# WKUP_VTM0_ECCAGGR_CFG register map
Vendor: Texas Instruments
Peripheral module from a debugger description file (folder J7VCL).
Registers are 32-bit, access not given, reset 0x0 unless marked. A register's access mark holds for its fields unless they carry their own. Offsets are as the file gives them; lines under a group give offsets from that group; [hi:lo] are bit positions; {n}, {i} and the like mark numbered series; 'fields as' and 'values as' point back to an identical list; <NAME> marks a mode.

## WKUP_VTM0_ECCAGGR_CFG
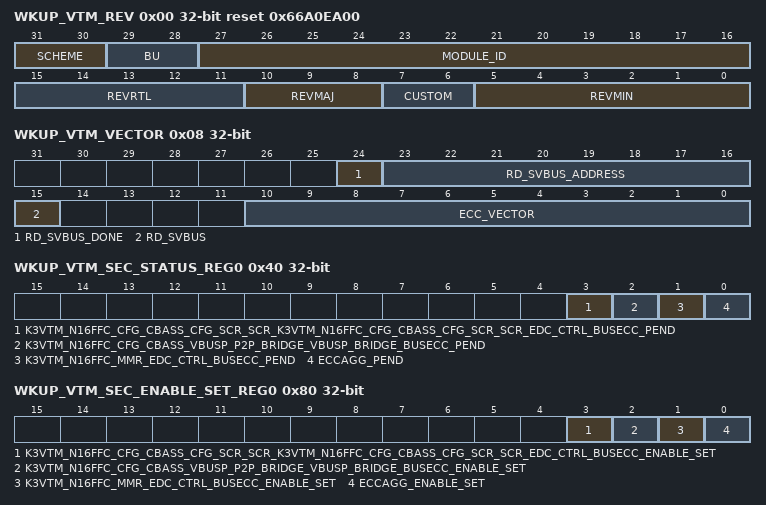
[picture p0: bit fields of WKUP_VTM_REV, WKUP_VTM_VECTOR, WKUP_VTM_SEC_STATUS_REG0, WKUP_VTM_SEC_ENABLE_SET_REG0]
0x00 WKUP_VTM_REV ro reset 0x66A0EA00 — Revision parameters
  [31:30] SCHEME
  [29:28] BU
  [27:16] MODULE_ID
  [15:11] REVRTL — RTL version
  [10:8] REVMAJ — Major version
  [7:6] CUSTOM — Custom version
  [5:0] REVMIN — Minor version
0x08 WKUP_VTM_VECTOR — ECC Register
  [24] RD_SVBUS_DONE — Status to indicate if read on serial VBUS is complete, write of any value will clear this bit. (access RW1C)
  [23:16] RD_SVBUS_ADDRESS rw — Read address
  [15] RD_SVBUS — Write 1 to trigger a read on the serial VBUS (access RW1S)
  [10:0] ECC_VECTOR rw — Value written to select the corresponding ECC RAM for control or status
0x0C WKUP_VTM_STAT ro reset 0x4 — Misc Status
  [10:0] NUM_RAMS — Indicates the number of RAMS serviced by the ECC aggregator
0x10 WKUP_VTM_RESERVED_SVBUS_y rw — Reference other documents that contain the ECC RAM wrapper and EDC controller serial vbus register sets. Offset = 10h + (y * 4h); where y = 0h to 7h
  [31:0] DATA — Serial VBUS register data
0x3C WKUP_VTM_SEC_EOI_REG — EOI Register The EOI register is used to re-trigger the pulse interrupt signal to ensure that any nested interrupt events are serviced. The software interrupt handler must write to the EOI register at the end of the current interrupt processing routine, so that new events can re-trigger the pulse interrupt signal again. For level interrupt signals the EOI register is not functional and must not be used.
  [0] EOI_WR — EOI Register (access RW1S)
0x40 WKUP_VTM_SEC_STATUS_REG0 — Interrupt Status Register 0
  [3] K3VTM_N16FFC_CFG_CBASS_CFG_SCR_SCR_K3VTM_N16FFC_CFG_CBASS_CFG_SCR_SCR_EDC_CTRL_BUSECC_PEND — Interrupt Pending Status for k3vtm_n16ffc_cfg_cbass_cfg_scr_scr_k3vtm_n16ffc_cfg_cbass_cfg_scr_scr_edc_ctrl_busecc_pend (access RW1S)
  [2] K3VTM_N16FFC_CFG_CBASS_VBUSP_P2P_BRIDGE_VBUSP_BRIDGE_BUSECC_PEND — Interrupt Pending Status for k3vtm_n16ffc_cfg_cbass_vbusp_p2p_bridge_vbusp_bridge_busecc_pend (access RW1S)
  [1] K3VTM_N16FFC_MMR_EDC_CTRL_BUSECC_PEND — Interrupt Pending Status for k3vtm_n16ffc_mmr_edc_ctrl_busecc_pend (access RW1S)
  [0] ECCAGG_PEND — Interrupt Pending Status for eccagg_pend (access RW1S)
0x80 WKUP_VTM_SEC_ENABLE_SET_REG0 — Interrupt Enable Set Register 0
  [3] K3VTM_N16FFC_CFG_CBASS_CFG_SCR_SCR_K3VTM_N16FFC_CFG_CBASS_CFG_SCR_SCR_EDC_CTRL_BUSECC_ENABLE_SET — Interrupt Enable Set Register for k3vtm_n16ffc_cfg_cbass_cfg_scr_scr_k3vtm_n16ffc_cfg_cbass_cfg_scr_scr_edc_ctrl_busecc_pend (access RW1S)
  [2] K3VTM_N16FFC_CFG_CBASS_VBUSP_P2P_BRIDGE_VBUSP_BRIDGE_BUSECC_ENABLE_SET — Interrupt Enable Set Register for k3vtm_n16ffc_cfg_cbass_vbusp_p2p_bridge_vbusp_bridge_busecc_pend (access RW1S)
  [1] K3VTM_N16FFC_MMR_EDC_CTRL_BUSECC_ENABLE_SET — Interrupt Enable Set Register for k3vtm_n16ffc_mmr_edc_ctrl_busecc_pend (access RW1S)
  [0] ECCAGG_ENABLE_SET — Interrupt Enable Set Register for eccagg_pend (access RW1S)
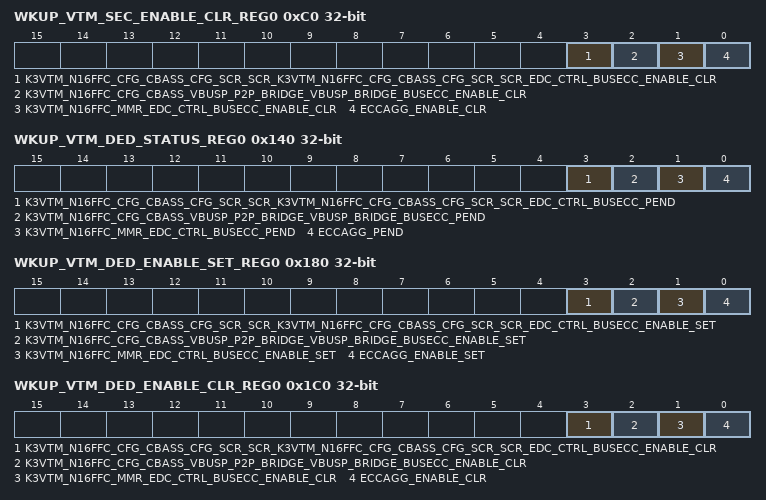
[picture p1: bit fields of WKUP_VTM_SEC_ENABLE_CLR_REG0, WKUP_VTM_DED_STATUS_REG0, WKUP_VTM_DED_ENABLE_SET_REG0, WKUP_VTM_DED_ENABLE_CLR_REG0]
0xC0 WKUP_VTM_SEC_ENABLE_CLR_REG0 — Interrupt Enable Clear Register 0
  [3] K3VTM_N16FFC_CFG_CBASS_CFG_SCR_SCR_K3VTM_N16FFC_CFG_CBASS_CFG_SCR_SCR_EDC_CTRL_BUSECC_ENABLE_CLR — Interrupt Enable Clear Register for k3vtm_n16ffc_cfg_cbass_cfg_scr_scr_k3vtm_n16ffc_cfg_cbass_cfg_scr_scr_edc_ctrl_busecc_pend (access RW1C)
  [2] K3VTM_N16FFC_CFG_CBASS_VBUSP_P2P_BRIDGE_VBUSP_BRIDGE_BUSECC_ENABLE_CLR — Interrupt Enable Clear Register for k3vtm_n16ffc_cfg_cbass_vbusp_p2p_bridge_vbusp_bridge_busecc_pend (access RW1C)
  [1] K3VTM_N16FFC_MMR_EDC_CTRL_BUSECC_ENABLE_CLR — Interrupt Enable Clear Register for k3vtm_n16ffc_mmr_edc_ctrl_busecc_pend (access RW1C)
  [0] ECCAGG_ENABLE_CLR — Interrupt Enable Clear Register for eccagg_pend (access RW1C)
0x13C WKUP_VTM_DED_EOI_REG — EOI Register The EOI register is used to re-trigger the pulse interrupt signal to ensure that any nested interrupt events are serviced. The software interrupt handler must write to the EOI register at the end of the current interrupt processing routine, so that new events can re-trigger the pulse interrupt signal again. For level interrupt signals the EOI register is not functional and must not be used.
  [0] EOI_WR — EOI Register (access RW1S)
0x140 WKUP_VTM_DED_STATUS_REG0 — Interrupt Status Register 0
  fields as WKUP_VTM_SEC_STATUS_REG0
0x180 WKUP_VTM_DED_ENABLE_SET_REG0 — Interrupt Enable Set Register 0
  fields as WKUP_VTM_SEC_ENABLE_SET_REG0
0x1C0 WKUP_VTM_DED_ENABLE_CLR_REG0 — Interrupt Enable Clear Register 0
  fields as WKUP_VTM_SEC_ENABLE_CLR_REG0
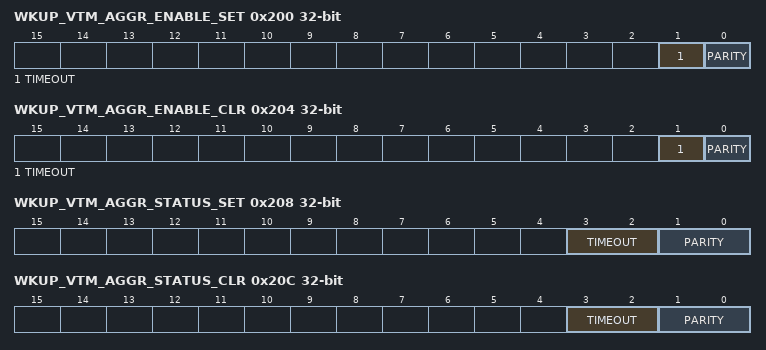
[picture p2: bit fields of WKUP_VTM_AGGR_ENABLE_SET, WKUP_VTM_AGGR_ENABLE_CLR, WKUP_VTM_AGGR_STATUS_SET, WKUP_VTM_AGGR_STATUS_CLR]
0x200 WKUP_VTM_AGGR_ENABLE_SET — AGGR interrupt enable set Register
  [1] TIMEOUT — interrupt enable set for svbus timeout errors (access RW1S)
  [0] PARITY — interrupt enable set for parity errors (access RW1S)
0x204 WKUP_VTM_AGGR_ENABLE_CLR — AGGR interrupt enable clear Register
  [1] TIMEOUT — interrupt enable clear for svbus timeout errors (access RW1C)
  [0] PARITY — interrupt enable clear for parity errors (access RW1C)
0x208 WKUP_VTM_AGGR_STATUS_SET — AGGR interrupt status set Register
  [3:2] TIMEOUT — interrupt status set for svbus timeout errors (access RWincr)
  [1:0] PARITY — interrupt status set for parity errors (access RWincr)
0x20C WKUP_VTM_AGGR_STATUS_CLR — AGGR interrupt status clear Register
  [3:2] TIMEOUT — interrupt status clear for svbus timeout errors (access RWdecr)
  [1:0] PARITY — interrupt status clear for parity errors (access RWdecr)
